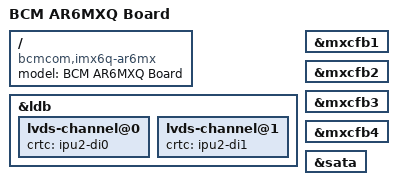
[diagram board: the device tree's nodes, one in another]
/*
 *
 * Copyright (C) 2014 Jasbir Matharu
 *
 * This program is free software; you can redistribute it and/or modify
 * it under the terms of the GNU General Public License version 2 as
 * published by the Free Software Foundation.
 *
 */

/dts-v1/;
#include "imx6q.dtsi"
#include "imx6qdl-ar6mx.dtsi"

/{
    model = "BCM AR6MXQ Board";
    compatible = "bcmcom,imx6q-ar6mx", "fsl,imx6q";
};

&ldb {
	lvds-channel@0 {
		crtc = "ipu2-di0";
	};

	lvds-channel@1 {
		crtc = "ipu2-di1";
	};
};

&mxcfb1 {
    status = "okay";
};

&mxcfb2 {
	status = "okay";
};

&mxcfb3 {
	status = "okay";
};

&mxcfb4 {
	status = "okay";
};

&sata {
	status = "okay";
};
